# LPC11Axx register map
File version: 0.6
CPU: CM0 r0p0, little endian, no MPU, no FPU, 2 interrupt priority bits
Registers are 32-bit, read-write, reset 0x0 unless marked. A register's access mark holds for its fields unless they carry their own. Offsets are from the block's base; [hi:lo] are bit positions.

## WWDT — Windowed Watchdog Timer (WWDT)
Base 0x40004000
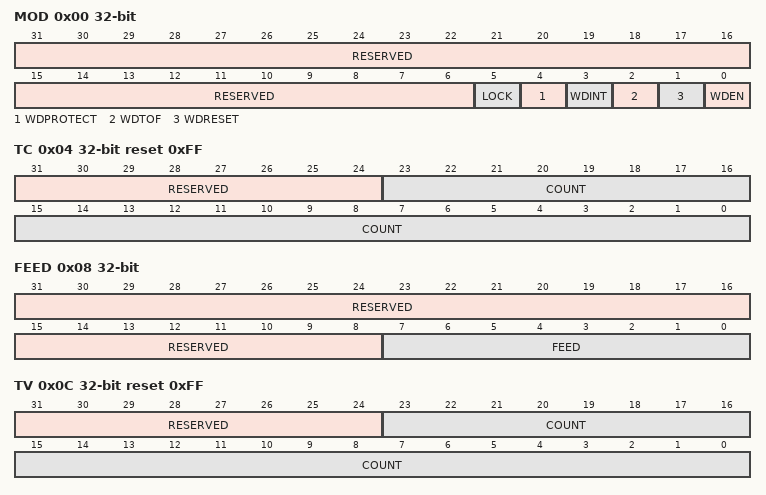
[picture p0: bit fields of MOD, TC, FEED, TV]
0x00 MOD — Watchdog mode register. This register contains the basic mode and status of the Watchdog Timer.
  [31:6] RESERVED — Reserved, user software should not write ones to reserved bits. The value read from a reserved bit is not defined.
  [5] LOCK — A 1 in this bit prevents disabling or powering down the clock source selected by bit 0 of the WDCLKSRC register and also prevents switching to a clock source that is disabled or powered down. This bit can be set once by software and is only cleared by any reset. If this bit is one and the WWDT clock source is the IRC when Deep-sleep or Power-down modes are entered, the IRC remains running thereby increasing power consumption in Deep-sleep mode and potentially preventing the part of entering Power-down mode correctly (see Section 15.7).
  [4] WDPROTECT — Watchdog update mode. This bit can be set once by software and is only cleared by a reset.
    0=NOT_LOCKED (The watchdog time-out value (TC) can be changed at any time.); 1=LOCKED (The watchdog time-out value (TC) can be changed only after the counter is below the value of WDWARNINT and WDWINDOW.)
  [3] WDINT — Warning interrupt flag. Set when the timer reaches the value in WDWARNINT. Cleared by software.
  [2] WDTOF — Watchdog time-out flag. Set when the watchdog timer times out, by a feed error, or by events associated with WDPROTECT. Cleared by software. Causes a chip reset if WDRESET = 1.
  [1] WDRESET — Watchdog reset enable bit. Once this bit has been written with a 1 it cannot be rewritten with a 0.
    0=INTERRUPT (A watchdog timeout will not cause a chip reset.); 1=RESET (A watchdog timeout will cause a chip reset.)
  [0] WDEN — Watchdog enable bit. Once this bit has been written with a 1 it cannot be rewritten with a 0.
    0=STOPPED (The watchdog timer is stopped.); 1=RUNNING (The watchdog timer is running.)
0x04 TC reset 0xFF — Watchdog timer constant register. This 24-bit register determines the time-out value.
  [31:24] RESERVED — Reserved, user software should not write ones to reserved bits. The value read from a reserved bit is not defined.
  [23:0] COUNT — Watchdog time-out value.
0x08 FEED wo reset not defined — Watchdog feed sequence register. Writing 0xAA followed by 0x55 to this register reloads the Watchdog timer with the value contained in WDTC.
  [31:8] RESERVED — Reserved, user software should not write ones to reserved bits. The value read from a reserved bit is not defined.
  [7:0] FEED — Feed value should be 0xAA followed by 0x55.
0x0C TV ro reset 0xFF — Watchdog timer value register. This 24-bit register reads out the current value of the Watchdog timer.
  [31:24] RESERVED — Reserved, user software should not write ones to reserved bits. The value read from a reserved bit is not defined.
  [23:0] COUNT — Counter timer value.
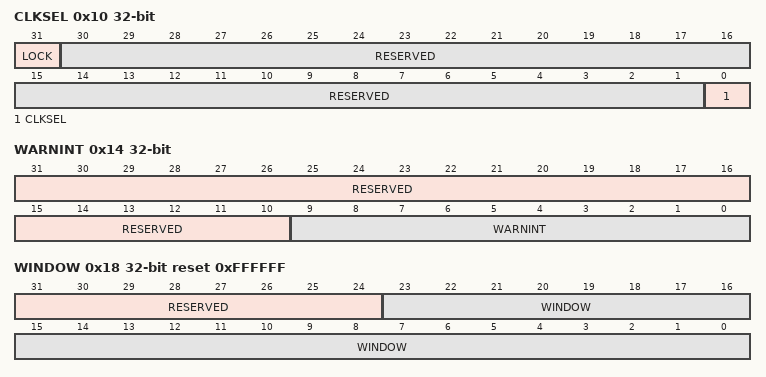
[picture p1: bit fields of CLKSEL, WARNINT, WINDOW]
0x10 CLKSEL — Watchdog clock select register.
  [31] LOCK — If this bit is set to one writing to this register does not affect bit 0. The clock source can only be changed by first clearing this bit, then writing the new value of bit 0.
  [30:1] RESERVED — Reserved, user software should not write ones to reserved bits. The value read from a reserved bit is not defined.
  [0] CLKSEL — Selects source of WDT clock
    0=IRC; 1=WATCHDOG_OSCILLATOR_ (Watchdog oscillator (WDOSC))
0x14 WARNINT — Watchdog Warning Interrupt compare value.
  [31:10] RESERVED — Reserved, user software should not write ones to reserved bits. The value read from a reserved bit is not defined.
  [9:0] WARNINT — Watchdog warning interrupt compare value.
0x18 WINDOW reset 0xFFFFFF — Watchdog Window compare value.
  [31:24] RESERVED — Reserved, user software should not write ones to reserved bits. The value read from a reserved bit is not defined.
  [23:0] WINDOW — Watchdog window value.
